# MSP432P401M register map
Vendor: Texas Instruments; File version: 3.230
CPU: 
Registers are 32-bit, read-write, reset 0x0 unless marked. A register's access mark holds for its fields unless they carry their own. Offsets are from the block's base; [hi:lo] are bit positions; {n}, {i} and the like mark numbered series.

## TIMER_A0
Base 0x40000000
Same registers: TIMER_A1 0x40000400, TIMER_A2 0x40000800, TIMER_A3 0x40000C00
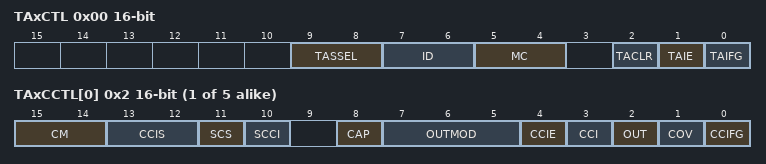
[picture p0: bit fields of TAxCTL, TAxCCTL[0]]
0x00 TAxCTL 16-bit — TimerAx Control Register
  [9:8] TASSEL — TimerA clock source select
    0=TAxCLK; 1=ACLK; 2=SMCLK; 3=INCLK
  [7:6] ID — Input divider
    0=/1; 1=/2; 2=/4; 3=/8
  [5:4] MC — Mode control
    0=Stop mode: Timer is halted; 1=Up mode: Timer counts up to TAxCCR0; 2=Continuous mode: Timer counts up to 0FFFFh; 3=Up/down mode: Timer counts up to TAxCCR0 then down to 0000h
  [2] TACLR — TimerA clear
  [1] TAIE — TimerA interrupt enable
    0=Interrupt disabled; 1=Interrupt enabled
  [0] TAIFG — TimerA interrupt flag
    0=No interrupt pending; 1=Interrupt pending
{0x2+2i} TAxCCTL[{i}] 16-bit (reset mask 0xFFF7) (i=0..4) — Timer_A Capture/Compare Control Register
  [15:14] CM — Capture mode
    0=No capture; 1=Capture on rising edge; 2=Capture on falling edge; 3=Capture on both rising and falling edges
  [13:12] CCIS — Capture/compare input select
    0=CCIxA; 1=CCIxB; 2=GND; 3=VCC
  [11] SCS — Synchronize capture source
    0=Asynchronous capture; 1=Synchronous capture
  [10] SCCI — Synchronized capture/compare input
  [8] CAP — Capture mode
    0=Compare mode; 1=Capture mode
  [7:5] OUTMOD — Output mode
    0=OUT bit value; 1=Set; 2=Toggle/reset; 3=Set/reset; 4=Toggle; 5=Reset; 6=Toggle/set; 7=Reset/set
  [4] CCIE — Capture/compare interrupt enable
    0=Interrupt disabled; 1=Interrupt enabled
  [3] CCI ro — Capture/compare input
  [2] OUT — Output
    0=Output low; 1=Output high
  [1] COV — Capture overflow
    0=No capture overflow occurred; 1=Capture overflow occurred
  [0] CCIFG — Capture/compare interrupt flag
    0=No interrupt pending; 1=Interrupt pending
0x10 TAxR 16-bit — TimerA register
{0x12+2i} TAxCCR[{i}] 16-bit (i=0..4) — Timer_A Capture/Compare Register
  [15:0] TAxR — TimerA register
0x20 TAxEX0 16-bit — TimerAx Expansion 0 Register
  [2:0] TAIDEX — Input divider expansion
    {v}=Divide by {v+1} (v=0..7)
0x2E TAxIV 16-bit ro — TimerAx Interrupt Vector Register
  [15:0] TAIV — TimerA interrupt vector value
    0=No interrupt pending; 2=Interrupt Source: Capture/compare 1; Interrupt Flag: TAxCCR1 CCIFG; Interrupt Priority: Highest; 4=Interrupt Source: Capture/compare 2; Interrupt Flag: TAxCCR2 CCIFG; 6=Interrupt Source: Capture/compare 3; Interrupt Flag: TAxCCR3 CCIFG; 8=Interrupt Source: Capture/compare 4; Interrupt Flag: TAxCCR4 CCIFG; 10=Interrupt Source: Capture/compare 5; Interrupt Flag: TAxCCR5 CCIFG; 12=Interrupt Source: Capture/compare 6; Interrupt Flag: TAxCCR6 CCIFG; 14=Interrupt Source: Timer overflow; Interrupt Flag: TAxCTL TAIFG; Interrupt Priority: Lowest

## REF_A
Base 0x40003000
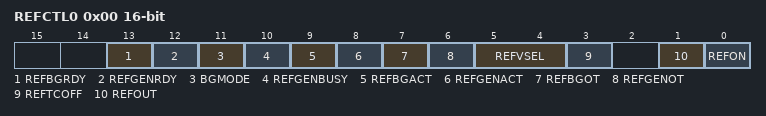
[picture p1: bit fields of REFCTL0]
0x00 REFCTL0 16-bit reset not defined — REF Control Register 0
  [13] REFBGRDY ro — Buffered bandgap voltage ready status
    0=Buffered bandgap voltage is not ready to be used; 1=Buffered bandgap voltage is ready to be used
  [12] REFGENRDY ro — Variable reference voltage ready status
    0=Reference voltage output is not ready to be used; 1=Reference voltage output is ready to be used
  [11] BGMODE ro — Bandgap mode
    0=Static mode; 1=Sampled mode
  [10] REFGENBUSY ro — Reference generator busy
    0=Reference generator not busy; 1=Reference generator busy
  [9] REFBGACT ro — Reference bandgap active
    0=Reference bandgap buffer not active; 1=Reference bandgap buffer active
  [8] REFGENACT ro — Reference generator active
    0=Reference generator not active; 1=Reference generator active
  [7] REFBGOT — Bandgap and bandgap buffer one-time trigger
    0=No trigger; 1=Generation of the bandgap voltage is started by writing 1 or by a hardware trigger
  [6] REFGENOT — Reference generator one-time trigger
    0=No trigger; 1=Generation of the reference voltage is started by writing 1 or by a hardware trigger
  [5:4] REFVSEL — Reference voltage level select
    0=1.2 V available when reference requested or REFON = 1; 1=1.45 V available when reference requested or REFON = 1; 3=2.5 V available when reference requested or REFON = 1
  [3] REFTCOFF — Temperature sensor disabled
    0=Temperature sensor enabled; 1=Temperature sensor disabled to save power
  [1] REFOUT — Reference output buffer
    0=Reference output not available externally; 1=Reference output available externally. If ADC14REFBURST = 0, output is available continuously. If ADC14REFBURST = 1, output is available only during an ADC14 conversion.
  [0] REFON — Reference enable
    0=Disables reference if no other reference requests are pending; 1=Enables reference in static mode
